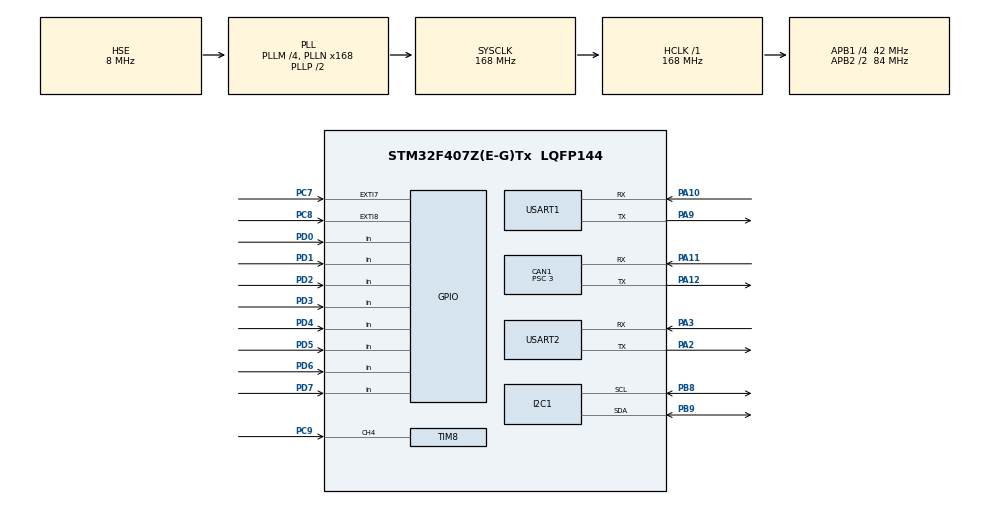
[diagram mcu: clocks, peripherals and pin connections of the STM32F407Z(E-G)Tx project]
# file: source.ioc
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CAN1.BS1=CAN_BS1_9TQ
CAN1.BS2=CAN_BS2_4TQ
CAN1.CalculateTimeBit=1000
CAN1.CalculateTimeQuantum=71.42857142857143
CAN1.Prescaler=3
Dma.MEMTOMEM.0.Direction=DMA_MEMORY_TO_MEMORY
Dma.MEMTOMEM.0.FIFOMode=DMA_FIFOMODE_ENABLE
Dma.MEMTOMEM.0.FIFOThreshold=DMA_FIFO_THRESHOLD_FULL
Dma.MEMTOMEM.0.Instance=DMA2_Stream0
Dma.MEMTOMEM.0.MemBurst=DMA_MBURST_SINGLE
Dma.MEMTOMEM.0.MemDataAlignment=DMA_MDATAALIGN_BYTE
Dma.MEMTOMEM.0.MemInc=DMA_MINC_ENABLE
Dma.MEMTOMEM.0.Mode=DMA_NORMAL
Dma.MEMTOMEM.0.PeriphBurst=DMA_PBURST_SINGLE
Dma.MEMTOMEM.0.PeriphDataAlignment=DMA_PDATAALIGN_BYTE
Dma.MEMTOMEM.0.PeriphInc=DMA_PINC_DISABLE
Dma.MEMTOMEM.0.Priority=DMA_PRIORITY_LOW
Dma.Request0=MEMTOMEM
Dma.Request1=TIM8_CH4/TRIG/COM
Dma.TIM8_CH4/TRIG/COM.1.Direction=DMA_PERIPH_TO_MEMORY
Dma.TIM8_CH4/TRIG/COM.1.FIFOMode=DMA_FIFOMODE_DISABLE
Dma.TIM8_CH4/TRIG/COM.1.Instance=DMA2_Stream7
Dma.TIM8_CH4/TRIG/COM.1.MemDataAlignment=DMA_MDATAALIGN_BYTE
Dma.TIM8_CH4/TRIG/COM.1.MemInc=DMA_MINC_ENABLE
Dma.TIM8_CH4/TRIG/COM.1.Mode=DMA_NORMAL
Dma.TIM8_CH4/TRIG/COM.1.PeriphDataAlignment=DMA_PDATAALIGN_BYTE
Dma.TIM8_CH4/TRIG/COM.1.PeriphInc=DMA_PINC_DISABLE
Dma.TIM8_CH4/TRIG/COM.1.Priority=DMA_PRIORITY_HIGH
Mcu.Family=STM32F4
Mcu.Name=STM32F407Z(E-G)Tx
Mcu.Package=LQFP144
NVIC.CAN1_RX0_IRQn=true\:0\:0\:false\:false\:true
NVIC.DMA2_Stream7_IRQn=true\:0\:0\:false\:false\:true
NVIC.EXTI9_5_IRQn=true\:0\:0\:false\:false\:true
NVIC.PriorityGroup=NVIC_PRIORITYGROUP_4
NVIC.USART1_IRQn=true\:0\:0\:false\:false\:true
NVIC.USART2_IRQn=true\:0\:0\:false\:false\:true
PA10.Mode=Asynchronous
PA10.Signal=USART1_RX
PA11.Mode=Master
PA11.Signal=CAN1_RX
PA12.Mode=Master
PA12.Signal=CAN1_TX
PA13.Mode=JTAG_4_pins
PA13.Signal=SYS_JTMS-SWDIO
PA14.Mode=JTAG_4_pins
PA14.Signal=SYS_JTCK-SWCLK
PA15.Mode=JTAG_4_pins
PA15.Signal=SYS_JTDI
PA2.Mode=Asynchronous
PA2.Signal=USART2_TX
PA3.Mode=Asynchronous
PA3.Signal=USART2_RX
PA9.Mode=Asynchronous
PA9.Signal=USART1_TX
PB3.Mode=JTAG_4_pins
PB3.Signal=SYS_JTDO-SWO
PB8.Mode=I2C
PB8.Signal=I2C1_SCL
PB9.Mode=I2C
PB9.Signal=I2C1_SDA
PC7.Signal=GPXTI7
PC8.GPIO_ModeDefaultEXTI=GPIO_MODE_IT_RISING
PC8.GPIO_PuPd=GPIO_PULLDOWN
PC8.Signal=GPXTI8
PC9.Signal=S_TIM8_CH4
PD0.Signal=GPIO_Input
PD1.Signal=GPIO_Input
PD2.Signal=GPIO_Input
PD3.Signal=GPIO_Input
PD4.Signal=GPIO_Input
PD5.Signal=GPIO_Input
PD6.Signal=GPIO_Input
PD7.Signal=GPIO_Input
PH0-OSC_IN.Mode=HSE-External-Oscillator
PH0-OSC_IN.Signal=RCC_OSC_IN
PH1-OSC_OUT.Mode=HSE-External-Oscillator
PH1-OSC_OUT.Signal=RCC_OSC_OUT
ProjectManager.HeapSize=0x200
ProjectManager.StackSize=0x400
ProjectManager.TargetToolchain=EWARM
RCC.48MHZClocksFreq_Value=84000000
RCC.AHBFreq_Value=168000000
RCC.APB1CLKDivider=RCC_HCLK_DIV4
RCC.APB1Freq_Value=42000000
RCC.APB1TimFreq_Value=84000000
RCC.APB2CLKDivider=RCC_HCLK_DIV2
RCC.APB2Freq_Value=84000000
RCC.APB2TimFreq_Value=168000000
RCC.CortexFreq_Value=168000000
RCC.HCLKFreq_Value=168000000
RCC.HSE_VALUE=8000000
RCC.HSI_VALUE=16000000
RCC.LSE_VALUE=32768
RCC.PLLM=4
RCC.PLLN=168
RCC.PLLSourceVirtual=RCC_PLLSOURCE_HSE
RCC.SYSCLKFreq_VALUE=168000000
RCC.SYSCLKSource=RCC_SYSCLKSOURCE_PLLCLK
RCC.VCOOutputFreq_Value=336000000
SH.S_TIM8_CH4.0=TIM8_CH4,Input_Capture4_from_TI4
TIM8.Channel-Input_Capture4_from_TI4=TIM_CHANNEL_4
USART1.VirtualMode=VM_ASYNC
USART2.VirtualMode=VM_ASYNC
board=source

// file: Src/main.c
/**
  ******************************************************************************
  * File Name          : main.c
  * Description        : Main program body
  ******************************************************************************
  ** This notice applies to any and all portions of this file
  * that are not between comment pairs USER CODE BEGIN and
  * USER CODE END. Other portions of this file, whether
  * inserted by the user or by software development tools
  * are owned by their respective copyright owners.
  *
  * COPYRIGHT(c) 2018 STMicroelectronics
  *
  * Redistribution and use in source and binary forms, with or without modification,
  * are permitted provided that the following conditions are met:
  *   1. Redistributions of source code must retain the above copyright notice,
  *      this list of conditions and the following disclaimer.
  *   2. Redistributions in binary form must reproduce the above copyright notice,
  *      this list of conditions and the following disclaimer in the documentation
  *      and/or other materials provided with the distribution.
  *   3. Neither the name of STMicroelectronics nor the names of its contributors
  *      may be used to endorse or promote products derived from this software
  *      without specific prior written permission.
  *
  * THIS SOFTWARE IS PROVIDED BY THE COPYRIGHT HOLDERS AND CONTRIBUTORS "AS IS"
  * AND ANY EXPRESS OR IMPLIED WARRANTIES, INCLUDING, BUT NOT LIMITED TO, THE
  * IMPLIED WARRANTIES OF MERCHANTABILITY AND FITNESS FOR A PARTICULAR PURPOSE ARE
  * DISCLAIMED. IN NO EVENT SHALL THE COPYRIGHT HOLDER OR CONTRIBUTORS BE LIABLE
  * FOR ANY DIRECT, INDIRECT, INCIDENTAL, SPECIAL, EXEMPLARY, OR CONSEQUENTIAL
  * DAMAGES (INCLUDING, BUT NOT LIMITED TO, PROCUREMENT OF SUBSTITUTE GOODS OR
  * SERVICES; LOSS OF USE, DATA, OR PROFITS; OR BUSINESS INTERRUPTION) HOWEVER
  * CAUSED AND ON ANY THEORY OF LIABILITY, WHETHER IN CONTRACT, STRICT LIABILITY,
  * OR TORT (INCLUDING NEGLIGENCE OR OTHERWISE) ARISING IN ANY WAY OUT OF THE USE
  * OF THIS SOFTWARE, EVEN IF ADVISED OF THE POSSIBILITY OF SUCH DAMAGE.
  *
  ******************************************************************************
  */
#include "main.h"
#include "stm32f4xx_hal.h"
#include "can.h"
#include "dma.h"
#include "i2c.h"
#include "tim.h"
#include "usart.h"
#include "gpio.h"

/* USER CODE BEGIN Includes */
#include "camera.h"

/* USER CODE END Includes */

/* USER CODE BEGIN PV */
/* Private variables ---------------------------------------------------------*/

/* USER CODE END PV */

void SystemClock_Config(void);

/* USER CODE BEGIN PFP */
/* Private function prototypes -----------------------------------------------*/

/* USER CODE END PFP */

int main(void)
{

  /* MCU Configuration----------------------------------------------------------*/

  /* Reset of all peripherals, Initializes the Flash interface and the Systick. */
  HAL_Init();

  /* Configure the system clock */
  SystemClock_Config();

  /* Initialize all configured peripherals */
  MX_GPIO_Init();
  MX_DMA_Init();
  MX_CAN1_Init();
  MX_I2C1_Init();
  MX_USART1_UART_Init();
  MX_USART2_UART_Init();
  MX_TIM8_Init();

  /* USER CODE BEGIN 2 */
  camera_init();
  uprintf("hello,world!\r\n");
  HAL_NVIC_SetPriority(EXTI9_5_IRQn, 3, 0);
  HAL_NVIC_EnableIRQ(EXTI9_5_IRQn);

  /* USER CODE END 2 */

  /* Infinite loop */
  while (1)
  {

    get_img();
    if(img_state==IMG_OK)
      vcan_sendimg(camera_buffer,600);

  }

}

/** System Clock Configuration
*/
void SystemClock_Config(void)
{

  RCC_OscInitTypeDef RCC_OscInitStruct;
  RCC_ClkInitTypeDef RCC_ClkInitStruct;

    /**Configure the main internal regulator output voltage
    */
  __HAL_RCC_PWR_CLK_ENABLE();

  __HAL_PWR_VOLTAGESCALING_CONFIG(PWR_REGULATOR_VOLTAGE_SCALE1);

    /**Initializes the CPU, AHB and APB busses clocks
    */
  RCC_OscInitStruct.OscillatorType = RCC_OSCILLATORTYPE_HSE;
  RCC_OscInitStruct.HSEState = RCC_HSE_ON;
  RCC_OscInitStruct.PLL.PLLState = RCC_PLL_ON;
  RCC_OscInitStruct.PLL.PLLSource = RCC_PLLSOURCE_HSE;
  RCC_OscInitStruct.PLL.PLLM = 4;
  RCC_OscInitStruct.PLL.PLLN = 168;
  RCC_OscInitStruct.PLL.PLLP = RCC_PLLP_DIV2;
  RCC_OscInitStruct.PLL.PLLQ = 4;
  if (HAL_RCC_OscConfig(&RCC_OscInitStruct) != HAL_OK)
  {
    _Error_Handler(__FILE__, __LINE__);
  }

    /**Initializes the CPU, AHB and APB busses clocks
    */
  RCC_ClkInitStruct.ClockType = RCC_CLOCKTYPE_HCLK|RCC_CLOCKTYPE_SYSCLK
                              |RCC_CLOCKTYPE_PCLK1|RCC_CLOCKTYPE_PCLK2;
  RCC_ClkInitStruct.SYSCLKSource = RCC_SYSCLKSOURCE_PLLCLK;
  RCC_ClkInitStruct.AHBCLKDivider = RCC_SYSCLK_DIV1;
  RCC_ClkInitStruct.APB1CLKDivider = RCC_HCLK_DIV4;
  RCC_ClkInitStruct.APB2CLKDivider = RCC_HCLK_DIV2;

  if (HAL_RCC_ClockConfig(&RCC_ClkInitStruct, FLASH_LATENCY_5) != HAL_OK)
  {
    _Error_Handler(__FILE__, __LINE__);
  }

    /**Configure the Systick interrupt time
    */
  HAL_SYSTICK_Config(HAL_RCC_GetHCLKFreq()/1000);

    /**Configure the Systick
    */
  HAL_SYSTICK_CLKSourceConfig(SYSTICK_CLKSOURCE_HCLK);

  /* SysTick_IRQn interrupt configuration */
  HAL_NVIC_SetPriority(SysTick_IRQn, 0, 0);
}

void _Error_Handler(char * file, int line)
{
  while(1)
  {
  }
}

/************************ (C) COPYRIGHT STMicroelectronics *****END OF FILE****/
